# FM33FG0XXA register map
File version: 1.0
CPU: SC000 r1p0, little endian, MPU, no FPU, 3 interrupt priority bits
Registers are 32-bit, read-only, reset 0x0 unless marked. A register's access mark holds for its fields unless they carry their own. Offsets are from the block's base; [hi:lo] are bit positions; {n}, {i} and the like mark numbered series.

## LPTIM32 — LPTIM32 module information
Base 0x40013400
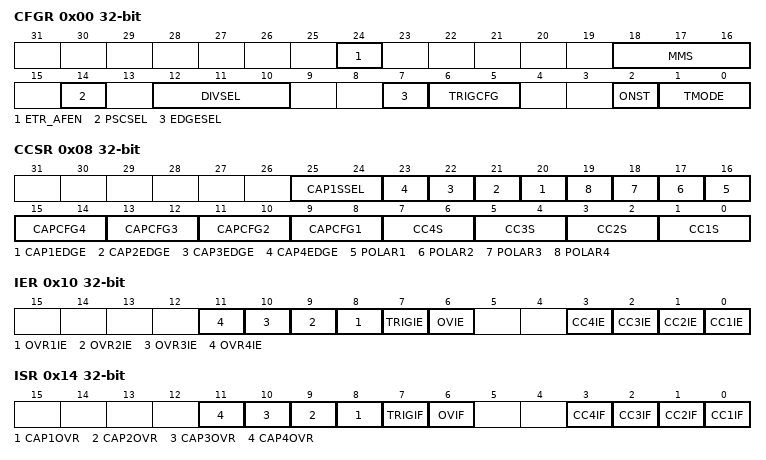
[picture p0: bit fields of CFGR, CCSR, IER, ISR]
0x00 CFGR rw — LPTIM32 Config Register
  [24] ETR_AFEN — ETR_AFEN field description
  [18:16] MMS — MMS field description
  [14] PSCSEL — PSCSEL field description
  [12:10] DIVSEL — DIVSEL field description
  [7] EDGESEL — EDGESEL field description
  [6:5] TRIGCFG — TRIGCFG field description
  [2] ONST — ONST field description
  [1:0] TMODE — TMODE field description
0x04 CNT — LPTIM32 Counter Register
  [31:0] CNT32 — CNT32 field description
0x08 CCSR access per field — LPTIM32 Capture/Compare Control and Status Register
  [25:24] CAP1SSEL rw — CAP1SSEL field description
  [n+19] CAP{n}EDGE ro (n=1..4) — CAP{n}EDGE field description
  [n+15] POLAR{n} rw (n=1..4) — POLAR{n} field description
  [2n+7:2n+6] CAPCFG{n} rw (n=1..4) — CAPCFG{n} field description
  [2n-1:2n-2] CC{n}S rw (n=1..4) — CC{n}S field description
0x0C ARR rw — LPTIM32 Auto-Reload Register
  [31:0] ARR — ARR field description
0x10 IER rw — LPTIM32 Interrupt Enable Register
  [n+7] OVR{n}IE (n=1..4) — OVR{n}IE field description
  [7] TRIGIE — TRIGIE field description
  [6] OVIE — OVIE field description
  [n-1] CC{n}IE (n=1..4) — CC{n}IE field description
0x14 ISR rw — LPTIM32 Interrupt Status Register
  [n+7] CAP{n}OVR (n=1..4) — CAP{n}OVR field description
  [7] TRIGIF — TRIGIF field description
  [6] OVIF — OVIF field description
  [n-1] CC{n}IF (n=1..4) — CC{n}IF field description
0x18 CR rw — LPTIM32 Control Register
  [0] EN — EN field description
{0x1C+4i} CCR{i} rw (i=1..4) — LPTIM32 Capture/Compare Register{i}
  [31:0] CCR{i} — CCR{i} field description

## LPTIM16 — LPTIM16 module information
Base 0x40018800
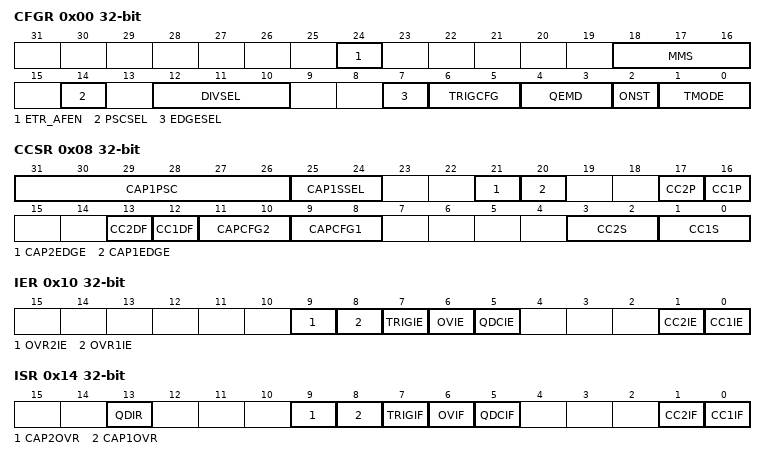
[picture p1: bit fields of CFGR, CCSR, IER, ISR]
0x00 CFGR rw — LPTIM16 Config Register
  [24] ETR_AFEN — ETR_AFEN field description
  [18:16] MMS — MMS field description
  [14] PSCSEL — PSCSEL field description
  [12:10] DIVSEL — DIVSEL field description
  [7] EDGESEL — EDGESEL field description
  [6:5] TRIGCFG — TRIGCFG field description
  [4:3] QEMD — QEMD field description
  [2] ONST — ONST field description
  [1:0] TMODE — TMODE field description
0x04 CNT — LPTIM16 Counter Register
  [15:0] CNT — CNT field description
0x08 CCSR access per field — LPTIM16 Capture/Compare Control and Status Register
  [31:26] CAP1PSC rw — CAP1PSC field description
  [25:24] CAP1SSEL rw — CAP1SSEL field description
  [21] CAP2EDGE ro — CAP2EDGE field description
  [20] CAP1EDGE ro — CAP1EDGE field description
  [17] CC2P rw — CC2P field description
  [16] CC1P rw — CC1P field description
  [13] CC2DF rw — CC2DF field description
  [12] CC1DF rw — CC1DF field description
  [11:10] CAPCFG2 rw — CAPCFG2 field description
  [9:8] CAPCFG1 rw — CAPCFG1 field description
  [3:2] CC2S rw — CC2S field description
  [1:0] CC1S rw — CC1S field description
0x0C ARR rw — LPTIM16 Auto-Reload Register
  [15:0] ARR — ARR field description
0x10 IER rw — LPTIM16 Interrupt Enable Register
  [9] OVR2IE — OVR2IE field description
  [8] OVR1IE — OVR1IE field description
  [7] TRIGIE — TRIGIE field description
  [6] OVIE — OVIE field description
  [5] QDCIE — QDCIE field description
  [1] CC2IE — CC2IE field description
  [0] CC1IE — CC1IE field description
0x14 ISR access per field — LPTIM16 Interrupt Status Register
  [13] QDIR ro — QDIR field description
  [9] CAP2OVR rw — CAP2OVR field description
  [8] CAP1OVR rw — CAP1OVR field description
  [7] TRIGIF rw — TRIGIF field description
  [6] OVIF rw — OVIF field description
  [5] QDCIF rw — QDCIF field description
  [1] CC2IF rw — CC2IF field description
  [0] CC1IF rw — CC1IF field description
0x18 CR rw — LPTIM16 Control Register
  [0] EN — EN field description
0x20 CCR1 rw — LPTIM16 Capture/Compare Register1
  [15:0] CCR1 — CCR1 field description
0x24 CCR2 rw — LPTIM16 Capture/Compare Register2
  [15:0] CCR2 — CCR2 field description
